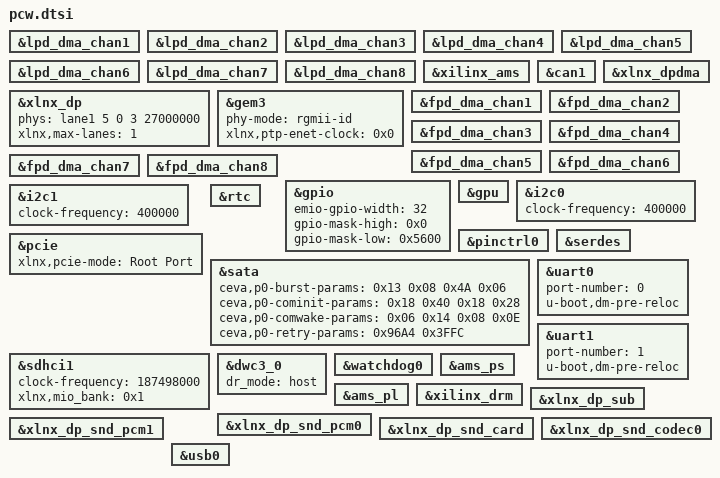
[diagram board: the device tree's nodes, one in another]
/*
 * CAUTION: This file is automatically generated by Xilinx.
 * Version:  
 * Today is: Thu Jul 26 12:03:48 2018
*/


&lpd_dma_chan1 {
	status = "okay";
};
&lpd_dma_chan2 {
	status = "okay";
};
&lpd_dma_chan3 {
	status = "okay";
};
&lpd_dma_chan4 {
	status = "okay";
};
&lpd_dma_chan5 {
	status = "okay";
};
&lpd_dma_chan6 {
	status = "okay";
};
&lpd_dma_chan7 {
	status = "okay";
};
&lpd_dma_chan8 {
	status = "okay";
};
&xilinx_ams {
	status = "okay";
};
&can1 {
	status = "okay";
};
&xlnx_dp {
	phy-names = "dp-phy0";
	phys = <&lane1 5 0 3 27000000>;
	status = "okay";
	xlnx,max-lanes = <1>;
};
&xlnx_dpdma {
	status = "okay";
};
&gem3 {
	phy-mode = "rgmii-id";
	status = "okay";
	xlnx,ptp-enet-clock = <0x0>;
};
&fpd_dma_chan1 {
	status = "okay";
};
&fpd_dma_chan2 {
	status = "okay";
};
&fpd_dma_chan3 {
	status = "okay";
};
&fpd_dma_chan4 {
	status = "okay";
};
&fpd_dma_chan5 {
	status = "okay";
};
&fpd_dma_chan6 {
	status = "okay";
};
&fpd_dma_chan7 {
	status = "okay";
};
&fpd_dma_chan8 {
	status = "okay";
};
&gpio {
	emio-gpio-width = <32>;
	gpio-mask-high = <0x0>;
	gpio-mask-low = <0x5600>;
	status = "okay";
};
&gpu {
	status = "okay";
};
&i2c0 {
	clock-frequency = <400000>;
	status = "okay";
};
&i2c1 {
	clock-frequency = <400000>;
	status = "okay";
};
&pinctrl0 {
	status = "okay";
};
&pcie {
	status = "okay";
	xlnx,pcie-mode = "Root Port";
};
&rtc {
	status = "okay";
};
&sata {
	ceva,p0-burst-params = "/bits/ 8 <0x13 0x08 0x4A 0x06>";
	ceva,p0-cominit-params = "/bits/ 8 <0x18 0x40 0x18 0x28>";
	ceva,p0-comwake-params = "/bits/ 8 <0x06 0x14 0x08 0x0E>";
	ceva,p0-retry-params = "/bits/ 16 <0x96A4 0x3FFC>";
	status = "okay";
};
&sdhci1 {
	clock-frequency = <187498000>;
	status = "okay";
	xlnx,mio_bank = <0x1>;
};
&serdes {
	status = "okay";
};
&uart0 {
	device_type = "serial";
	port-number = <0>;
	status = "okay";
	u-boot,dm-pre-reloc ;
};
&uart1 {
	device_type = "serial";
	port-number = <1>;
	status = "okay";
	u-boot,dm-pre-reloc ;
};
&dwc3_0 {
	dr_mode = "host";
	status = "okay";
};
&watchdog0 {
	status = "okay";
};
&ams_ps {
	status = "okay";
};
&ams_pl {
	status = "okay";
};
&xilinx_drm {
	status = "okay";
};
&xlnx_dp_sub {
	status = "okay";
};
&xlnx_dp_snd_pcm0 {
	status = "okay";
};
&xlnx_dp_snd_pcm1 {
	status = "okay";
};
&xlnx_dp_snd_card {
	status = "okay";
};
&xlnx_dp_snd_codec0 {
	status = "okay";
};
&usb0 {
	status = "okay";
};
